# LEA_SC_367.0 register map
Vendor: Texas Instruments
Peripheral module from a debugger description file (folder msp430).
Registers are 32-bit, read-write, no defined reset value unless marked. A register's access mark holds for its fields unless they carry their own. Offsets are as the file gives them; lines under a group give offsets from that group; [hi:lo] are bit positions; {n}, {i} and the like mark numbered series; 'fields as' and 'values as' point back to an identical list; <NAME> marks a mode.

## LEA_SC
0x00 LEASCCAP ro — LEASC Capability Register
  [3:0] LEAMSIZ — LEA Code Memory Size. This register identifies the size of available code RAM
    0=no code RAM; 1=1KB Code RAM
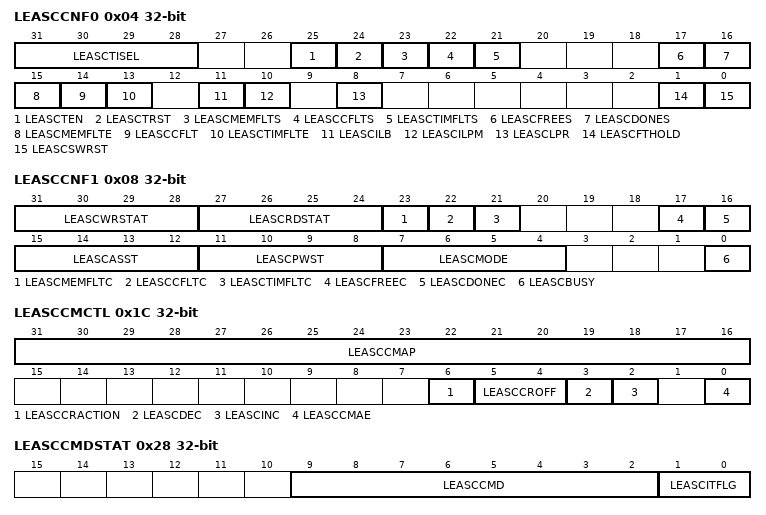
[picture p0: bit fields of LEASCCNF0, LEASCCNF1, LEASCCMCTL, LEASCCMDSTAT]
0x04 LEASCCNF0 access per field — Configuration Register 0
  [31:28] LEASCTISEL rw — LEA timer interval select. These bits select LEA timer interval. t#sub#CLK#/sub# = 1 / f#sub#CLK#/sub# f#sub#CLK#/sub# = MCLK
    0=Timeout period: 128 x t#sub#CLK#/sub# (16 us at 8 MHz); Interval period: 256 x t#sub#CLK#/sub# (32 us at 8 MHz); 1=Timeout period: 256 x t#sub#CLK#/sub# (32 us at 8 MHz); Interval period: 512 x t#sub#CLK#/sub# (64 us at 8 MHz); 2=Timeout period: 512 x t#sub#CLK#/sub# (64 us at 8 MHz); Interval period: 1024 x t#sub#CLK#/sub# (128 us at 8 MHz); 3=Timeout period: 1024 x t#sub#CLK#/sub# (128 us at 8 MHz); Interval period: 2048 x t#sub#CLK#/sub# (256 us at 8 MHz); 4=Timeout period: 2048 x t#sub#CLK#/sub# (256 us at 8 MHz); Interval period: 4096 x t#sub#CLK#/sub# (512 us at 8 MHz); 5=Timeout period: 4096 x t#sub#CLK#/sub# (512 us at 8 MHz); Interval period: 8192 x t#sub#CLK#/sub# (1ms at 8 MHz); 6=Timeout period: 8192 x t#sub#CLK#/sub# (1 ms at 8 MHz); Interval period: 16384 x t#sub#CLK#/sub# (2 ms at 8 MHz); 7=Timeout period: 16384 x t#sub#CLK#/sub# (2 ms at 8 MHz); Interval period: 32768 x t#sub#CLK#/sub# (4 ms at 8 MHz); 8=Timeout period: 32768 x t#sub#CLK#/sub# (4ms at 8 MHz); Interval period: 65536 x t#sub#CLK#/sub# (8 ms at 8 MHz); 9=Timeout period: 65536 x t#sub#CLK#/sub# (8 ms at 8 MHz); Interval period: 131072 x t#sub#CLK#/sub# (16 ms at 8 MHz); 10=Timeout period: 131072 x t#sub#CLK#/sub# (16 ms at 8 MHz); Interval period: 262144 x t#sub#CLK#/sub# (32 ms at 8 MHz); 11=Timeout period: 524288 x t#sub#CLK#/sub# (65 ms at 8 MHz); Interval period: 1048576 x t#sub#CLK#/sub# (131 ms at 8 MHz); 12=Timeout period: 1048576 x t#sub#CLK#/sub# (131 ms at 8 MHz); Interval period: 2097152 x t#sub#CLK#/sub# (262 ms at 8 MHz); 13=Timeout period: 2097152 x t#sub#CLK#/sub# (262 ms at 8 MHz); Interval period: 4194304 x t#sub#CLK#/sub# (524 ms at 8 MHz); 14=Timeout period: 4194304 x t#sub#CLK#/sub# (524 ms at 8 MHz); Interval period: 8388608 x t#sub#CLK#/sub# (1.05 s at 8 MHz); 15=Timeout period: 8388608 x t#sub#CLK#/sub# (1.05 s at 8 MHz); Interval period: 16777216 x t#sub#CLK#/sub# (2.1 s at 8 MHz)
  [25] LEASCTEN rw — LEA_SC timer enable; writing a one to this bit enables LEA_SC timer operations.
  [24] LEASCTRST rw — LEA_SC module timer reset. Setting this bit to one clears LEA_SC module timer. This bit is self clearing and will always be read as zero.
  [23] LEASCMEMFLTS rw — LEA_SC memory fault indication and set flag. This bit indicates that a fault in the memory VBUS interface occurred. The exact fault reason may be identified by checking LEASCCNF1. LEASCWRSTAT and LEASCCNF1.LEASCRDSTAT.
    0=No memory fault occurred since this bit was cleared; 1=At least one memory fault since this bit was cleared
  [22] LEASCCFLTS rw — LEASCHPCFLTS when hardware trigger enabled later LEA_SC command fault on peripheral interface or hardware triggered indication and set flag; This bits indicates that a command was invoked that is not implemented. This fault is also signaled to the SYS module as a "User-NMI" when enabled. Only one fault condition is signaled until this bit is cleared. Leaving this bit set will not cause any further faults. This fault may also be set by writing a one to it. Writing a zero has no effect.The corresponding terminal is connected to one of the UNMI inputs of the SYS module.
    0=No command fault occurred since this bit was cleared; 1=At least one command fault occurred since this bit was cleared
  [21] LEASCTIMFLTS rw — LEA_SC timeout fault indication and set flag; This bits indicates that timer timeout occurred. This fault may also be set by writing a one to it. Writing a zero has no effect.The corresponding terminal is connected to one of the UNMI inputs of the SYS module (A package option)
  [17] LEASCFREES rw — LEA_SC free event indication and set flag. This bit indicated the free event for LEA_SC. This bit can be set by writing a one to it. Writing a zero has no effect.
  [16] LEASCDONES rw — LEA_SC done event indication and set flag. This bit indicated the done event for LEA_SC. This bit can be set by writing a one to it. Writing a zero has no effect.
  [15] LEASCMEMFLTE rw — Enable bit on memory faults.
    0=LEA_SC memory faults are disabled; 1=LEA_SC memory faults are enabled
  [14] LEASCCFLT rw — LEASCHPCFLTE when hardware trigger available later Enable bit on peripheral mapped command faults and hardware triggered command faults.
    0=LEASCHPCFLT is disabled; 1=LEASCHPCFLT is enabled
  [13] LEASCTIMFLTE rw — LEA_SC module timer fault enable.
    0=LEASCTIMFLT_0 (LEA_SC module timer timeout will not cause a fault indication); 1=LEA_SC module timer timeout will cause a fault indication. LEA_SC stops operation and enters "Ready-state".
  [11] LEASCILB ro — LEA_SC instruction loop buffer disable. Debugging function for LEA_SC (leave it zero).
  [10] LEASCILPM rw — This bit defines if a "Command done interrupt" shall be triggered in LPM mode
    0=Interrupt of LEA-SC is suppressed in LPM mode until AM is entered then the LEA-SC interrupt is triggered as well; 1=Interrupt of LEA-SC is always triggered on completion of an LEA command
  [8] LEASCLPR rw — This bit defined if command execution shall be continued in LPM modes
    0=LEA-SC command execution stops in deep low power modes; 1=LEA-SC command execution continues in deep low power modes
  [1] LEASCFTHOLD rw — Hold on faults and NMIs for all pending LEA_SC operations transfers.This is for all system wide fault/NMI cases (for our first implementation we may just consider local LEA triggered fault cases)
    0=LEA-SC transfers continue on faults/NMIs; 1=LEA-SC transfers enter HOLD on faults/NMIs
  [0] LEASCSWRST rw — LEA_SC module software restart. Setting this bit to one restarts the LEA_SC module. As long this bit remains set to one the LEA-SC is held in Restart. (The LEA_SC accessible memory behaves as system RAM)
0x08 LEASCCNF1 access per field — Configuration Register 1
  [31:28] LEASCWRSTAT ro — Write Status. This bit field keeps the VBUS write status lines from the last bus error condition.
  [27:24] LEASCRDSTAT ro — Read Status. This bit field keeps the VBUS read status lines from the last bus error condition.
  [23] LEASCMEMFLTC rw — LEA_SC memory fault indication and clear flag. This bit indicates that a fault in the memory VBUS interface occurred. The exact fault reason may be identified by checking LEASCWRSTAT and LEASCRDSTAT. This fault is also signaled to the SYS-module as bus error when enabled (LEASCCNF0.LEASCMEMFLTE=1). Only one fault condition is signaled until this bit is cleared. Leaving this bit set will not cause any further faults. This fault is cleared by writing a one to it. Writing a zero has no effect.
    values as LEASCCNF0.LEASCMEMFLTS
  [22] LEASCCFLTC rw — LEA-SC command fault
    values as LEASCCNF0.LEASCCFLTS
  [21] LEASCTIMFLTC rw — LEA_SC timeout fault indication and clear flag; This bits indicates that a timer timeout occurred. This fault is cleared by writing a one to it. Writing a zero has no effect..
  [17] LEASCFREEC rw — LEA_SC free event indication and clear flag. This bit indicated the free event for LEA_SC. This bit is cleared by writing a one to it. Writing a zero has no effect.
  [16] LEASCDONEC rw — LEA_SC done event indication and clear flag. This bit indicated the done event for LEA_SC. This bit is cleared by writing a one to it. Writing a zero has no effect.
  [15:12] LEASCASST ro — These bits are used to store the internal state of the application specific processor (ASIP) inside the accelerator core. The specific meaning of those bit patterns is not shown in this document.
  [11:8] LEASCPWST ro — These bits indicate the current power consumption as a relative value. The value zero indicated only static operation (usually clock less). This register might be read out for statistical power estimation of an application. These bits are also reflected in J-STATE when debugging
  [7:4] LEASCMODE ro — These Bits indicate the actual operation mode LEA_SC is in. Other = Reserved
    0=OFF (Off (implicit)); 1=READY; 2=RUNS (RunS (SUSPEND)); 3=RUNR (RunR (RESUME)); 4=RUNA (RunA (regular command operation )); 5=NOTIFY; 6=SLEEP; 7=RUNL
  [0] LEASCBUSY ro — This bit indicate if LEA_SC is able to accept new Commands (SUSPEND is always accepted)
    0=READY (LEA_SC is in Ready can accept new commands); 1=BUSY (LEA_SC is busy right now and cannot accept any commands)
0x0C LEASCCNF2 — Configuration Register 2
  [15:0] LEASCSPTR — LEA_SC stack pointer value (byte units). 64 lower kB is physical limit for LEA application complexity
0x10 LEASCMB ro — Memory Bottom Register
  [15:0] LEASCMB — LEA_SC memory bottom address boundary in byte address units
0x14 LEASCMT ro — Memory Top Register
  [15:0] LEASCMT — LEA_SC memory top address boundary in byte address units
0x18 LEASCCMA access not given — Code Memory Access Register
0x1C LEASCCMCTL — Code Memory Control Register
  [31:16] LEASCCMAP — LEA_SC code memory address port. This bit field points to the memory location that is accessible via LEASCCMDP
  [6] LEASCCRACTION — Code RAM action
  [5:4] LEASCCROFF — Control bits only available if LEA code RAM is available. Otherwise reserved. Reserved. Read back as 0
    0=Contents of LEA-SC code RAM are retained in LPM3/LPM4; 1=Turns off the LEA-SC code RAM in LPM3/LPM4, re-activates it on wake-up. All data of the code RAM is lost after wakeup from LPM3/LPM4. See the device specific data sheet for presence and size of Code RAM.; 2=Turns off the code RAM entering LPM3/LPM4, the code RAM sector remains off after wake-up. All data of the code RAM is lost. See the device-specific data sheet for presence and size of Code RAM.
  [3] LEASCDEC — This bit when set causes the code memory address port field LEASCCMAP to decrement each time after an access to LEASCCMDP is performed.The decrement is by value two on 16B accesses on lower word of LEASCCMA.The decrement is by value two on 32B accesses on LEASCCMA.#b#Note:#/b# A double decrement is performed when read modify write accesses are done on LEASCCMDP.
  [2] LEASCINC — This bit when set causes the code memory address port field LEASCCMAP to increment each time after an access to LEASCCMDP is performed.The decrement is by value two on 16B accesses on lower word of LEASCCMA.The decrement is by value two on 32B accesses on LEASCCMA.#b#Note:#/b# A double increment is performed when read modify write accesses are done on LEASCCMDP.
  [0] LEASCCMAE — This bit controls access to LEA_SC code memory.
    0=Code memory access disabled. Accesses to LEA_SC code memory are not possible. LEA_SC does accept commands for execution. Reads to LEA_SC code memory will return zeroes and writes are ignored.; 1=Code memory access enabled. Accesses to LEA_SC code memory are possible. LEA_SC does not accept commands during this mode (command is ignored). Coprocessor interface accesses by the CPU cause a Coprocessor not available indication.
0x28 LEASCCMDSTAT ro — LEA Command Status Register
  [9:2] LEASCCMD — These bits represent the LEA_SC command to be invoked. See also the command table
    0=SUSPEND (Suspends ongoing action an enters Ready); 2=RESUME (Resumes an previously suspended command execution); 4=FFTCOMPLEXFIXEDSCALING (Complex FFT on 16 bit fractional numbers fix scaling); 6=FIR (Real FIR on 16 bit fractional numbers); 8=POLYNOMIAL (Real vector polynomial calculations 16 args all fractional); 10=FFT (Real FFT-extension on 16 bit fractional numbers); 12=POLYNOMIALLONG (Real vector polynomial calculations 32 bit args all fractional); 13=MPYMATRIXROW (Real row oriented matrix multiply); 15=MPYMATRIX (Real matrix multiply 16 with 16 to 16 bit fractional); 16=ADDMATRIX (Real point wise matrix add of 16 and 16 to 16 bit number vector); 17=MAXMATRIX (Real maximum value and position of 16 bit matrices); 18=MINMATRIX (Real minimum value and position of 16 bit matrices); 19=IIRBQ1 (Real second order biquad using DF1 with 16 bit fractional); 21=MAC (Real matrix MAC short with 16Bt to 16B fract); 22=DEINTERLEAVEEVENEVEN (Split 16B vector even to even words); 23=DEINTERLEAVEEVENODD (Split 16Bt vector even to odd words); 24=DEINTERLEAVEODDEVEN (Split 16B vector odd to even words); 25=DEINTERLEAVEODDODD (Split 16B vector odd to odd words); 26=MACCOMPLEXMATRIX (Complex Dot Product); 27=MACCOMPLEXCONJUGATEMATRIX (Complex conjugate Dot Product); 28=SUBMATRIX (Real point wise matrix Subtraction of 16 and 16 to 16 bit); 29=MPYLONGMATRIX (Real point wise matrix multiply 32 with 32 to 32 bit fractional); 30=MPYCOMPLEXMATRIX (Complex point wise matrix multiply complex with complex); 31=ADDLONGMATRIX (Real point wise matrix add of 32 and 32 to 32 bit number); 32=MOVELONGLIST (List move 32 to 32 bit); 33=BITREVERSECOMPLEXEVEN (Complex bit reversal for 16 bit fractional numbers even); 34=BITREVERSECOMPLEXODD (Complex bit reversal for 16 bit fractional Numbers odd); 36=IIRBQ2EXTENDED (Real second order biquad using DF2 with 16 bit fractional, extended to include bias and intermediate state min/max); 39=FFTCOMPLEXLONG (Complex FFT on 32B bit fractional numbers, fix scaling); 41=FFTLONG (Real FFT-extension on 32 bit fractional numbers); 43=BITREVERSECOMPLEXLONGEVEN (Complex bit reversal for 32 bit fractional numbers even); 45=BITREVERSECOMPLEXLONGODD (Complex bit reversal for 16 bit fractional numbers odd); 47=POLYNOMIALSCALAR (Scalar Polynomial for math on 32bit fractional); 48=FFTCOMPLEXAUTOSCALING (Complex FFT on 16B bit fractional numbers with auto scaling for enhanced accuracy); 50=FIRLONG (Real FIR on 32 bit fractional numbers); 52=MACLONGMATRIX (Real block MAC on 32B fractional numbers); 53=SUBLONGMATRIX (Real point wise matrix Subtraction of 32 and 32 to 32 bit); 54=MAXLONGMATRIX (Real maximum value and position of signed 32B matrices); 55=MINLONGMATRIX (Real minimum value and position of signed 32B matrices); 56=FIRCOMPLEX (Complex FIR on 16B fractional numbers); 58=MAXUNSIGNEDMATRIX (Real maximum value and position of unsigned 16B matrices); 59=MINUNSIGNEDMATRIX (Real minimum value and position of unsigned 32B matrices); 64=MACMATRIX (Real Matrix MAC on 16B fractional); 65=MAX (Vector maximum on 16B signed numbers); 66=MIN (Vector minimum on 16B signed numbers); 67=MAXUNSIGNED (Vector maximum on 16B unsigned numbers); 68=MINUNSIGNED (Vector minimum on 16B unsigned numbers); 69=MAXUNSIGNEDLONGMATRIX (Matrix maximum on 32B unsigned numbers); 70=MINUNSIGNEDLONGMATRIX (Matrix minimum on 32B unsigned numbers); 71=IIRBQ2 (Real second order biquad using DF2 with 16 bit fractional); 73=FIRCOMPLEXLONG (Complex FIR on 32B fractional numbers); 75=DEINTERLEAVELONG (Split Function on 32B Vectors/Matrices); 76=WINDOW (In-place symmetrical window on 16B fractional numbers); 77=MAC3 (Vector MAC at three points, real 16-bit with 32-bit result); 78=SCALEDMAC (Scaled vector multiply and accumulate (MAC)); 79=SCALEDFIR (Scaled FIR, 16-bit real fractional numbers)
  [1:0] LEASCITFLG — LEA_SC instruction handshake synchronization type flags
    0=LEA_SC command without any further indication; 1=LEA_SC command with explicit result update; 2=LEA_SC command with interrupt upon completion; 3=LEA_SC command with interrupt and explicit result update
0x2C LEASCS1STAT access not given — LEA Source 1 Status Register
0x30 LEASCS0STAT access not given — LEA Source 0 Status Register
0x34 LEASCDSTSTAT access not given — LEA Result Status Register
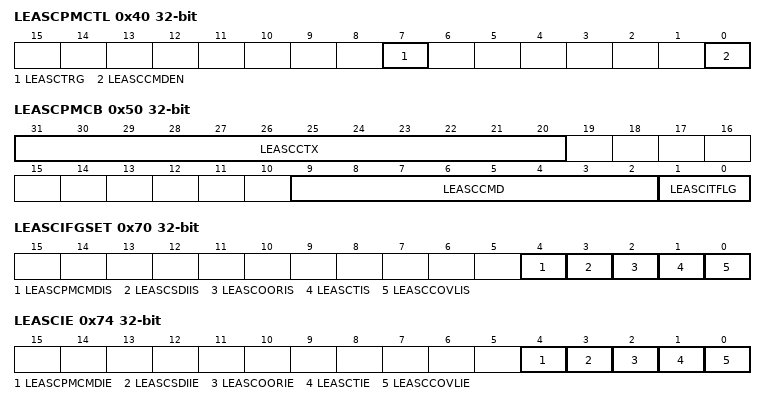
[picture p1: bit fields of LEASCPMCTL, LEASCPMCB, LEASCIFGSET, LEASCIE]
0x40 LEASCPMCTL access per field — PM Control Register
  [7] LEASCTRG ro — Command trigger
  [0] LEASCCMDEN rw — Command enable
    0=Command triggering by writing to LEASCPMCB is disabled; 1=Command triggering by writing to LEASCPMCB is enabled
0x44 LEASCPMDST access not given — PM Result Register
0x48 LEASCPMS1 access not given — PM Source 1 Register
0x4C LEASCPMS0 access not given — PM Source 0 Register
0x50 LEASCPMCB — PM Command Buffer Register
  [31:20] LEASCCTX — Command context: This bit field may be set by the user together with invoking a command. This bit field is saved on SUSPEND; and restored from LEA_SC Stack on RESUME. This bit field is used by SW to associate or synchronize LEA_SC commands to a certain tasks and IDs.
  [9:2] LEASCCMD — These bits represent the LEA_SC command to be invoked. See also the command table
    values as LEASCCMDSTAT.LEASCCMD
  [1:0] LEASCITFLG — LEA_SC instruction handshake synchronization type flag
    0=LEA-SC command without any further indication; 1=LEA-SC command with explicit result update; 2=LEA-SC command with interrupt upon completion; 3=LEA-SC command with interrupt and explicit result update
0x70 LEASCIFGSET — Interrupt Flag and Set Register
  [all] fields
    0=No interrupt pending; 1=Interrupt pending
  [4] LEASCPMCMDIS — PMCMD as soon hardware trigger is avail. Peripheral memory triggered Command completed interrupt flag.
  [3] LEASCSDIIS — LEA_SC scalar data inconsistency interrupt flag
  [2] LEASCOORIS — LEA_SC out of address range interrupt flag.
  [1] LEASCTIS — LEA_SC timer interrupt flag
  [0] LEASCCOVLIS — LEA_SC command overflow interrupt flag
0x74 LEASCIE — Interrupt Enable Register
  [all] fields
    0=Interrupt disabled; 1=Interrupt enabled
  [4] LEASCPMCMDIE — PMCMD as soon hardware trigger is avail. Peripheral memory triggered Command completed interrupt enable.
  [3] LEASCSDIIE — LEA_SC scalar data inconsistency interrupt enable
  [2] LEASCOORIE — LEA_SC out of address range interrupt enable.
  [1] LEASCTIE — LEA_SC timer event interrupt enable
  [0] LEASCCOVLIE — LEA_SC command overflow interrupt enable
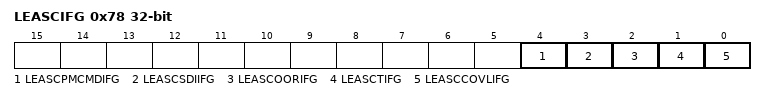
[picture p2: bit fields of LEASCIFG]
0x78 LEASCIFG — Interrupt Flag and Clear Register
  [all] fields
    0=No interrupt pending; 1=Interrupt pending
  [4] LEASCPMCMDIFG — PMCMD when hardware trigger is available. Peripheral memory triggered Command completed interrupt flag.
  [3] LEASCSDIIFG — LEA_SC scalar data inconsistency interrupt flag
  [2] LEASCOORIFG — LEA_SC out of address range interrupt flag.
  [1] LEASCTIFG — LEA_SC timer interrupt flag
  [0] LEASCCOVLIFG — LEA_SC command overflow interrupt flag
0x7C LEASCIV — Interrupt Vector Register
  [7:0] LEASCIV — LEA-SC interrupt vector. This is a generated value that can be used as address offset for fast interrupt service routine handling. Reading this register clears the highest pending LEA-SC interrupt (displaying this register with an IDE does not affect its content). Writing to this register clears al pending interrupt flags.This value is always aligned to a 20 bit address offset boundary
    0=NONE (No interrupt pending); 2=COVLIFG (LEA command overflow); 4=TIFG (LEA timer interrupt); 6=OORIFG (LEA out of range interrupt); 8=SDIIFG (LEA scalar data inconsistency); 10=PMCMDIFG (PMCMD complete interrupt)
